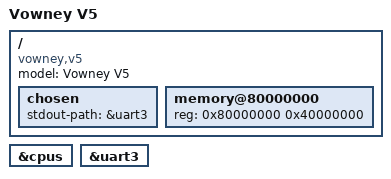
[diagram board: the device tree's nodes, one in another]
// SPDX-License-Identifier: BSD-3-Clause
/*
 * Copyright (c) 2024, Balazs Vinarz <vinibali1@gmail.com>
 */

/dts-v1/;
#include "mt6589.dtsi"

/ {
	model = "Vowney V5";
	compatible = "vowney,v5", "mediatek,mt6589";

	chosen {
		stdout-path = &uart3;
	};

	memory@80000000 {
		device_type = "memory";
		reg = <0x80000000 0x40000000>;
	};
};

&cpus {
	/* SMP is not stable on this board, makes the kernel panic */
  /* This is coming from Fairphone's DTS */
	/delete-property/ enable-method;
};

&uart3 {
	status = "okay";
};
